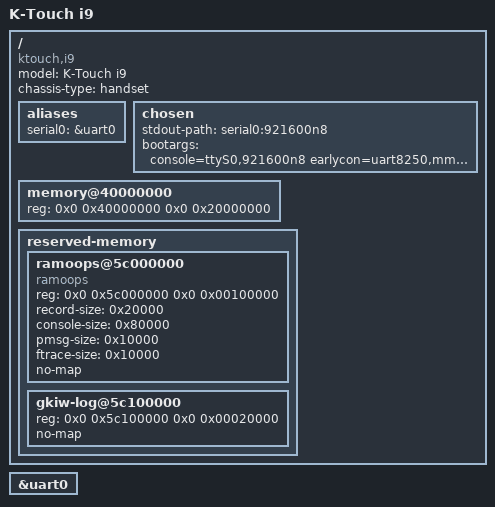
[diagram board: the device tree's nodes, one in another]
// SPDX-License-Identifier: GPL-2.0-only
/*
 * K-Touch i9 (MT6739)
 *
 * First mainline boot milestone: CPUs, GIC, timer, PSCI, UART and pstore.
 * The 2ndstage U-Boot boots this image at 0x45000000 and reserves the pstore
 * region below at 0x5c000000.
 */

/dts-v1/;

#include "mt6739.dtsi"

/ {
	model = "K-Touch i9";
	compatible = "ktouch,i9", "mediatek,mt6739";
	chassis-type = "handset";

	aliases {
		serial0 = &uart0;
	};

	chosen {
		stdout-path = "serial0:921600n8";
		bootargs = "console=ttyS0,921600n8 earlycon=uart8250,mmio32,0x11002000,921600n8 keep_bootcon ignore_loglevel loglevel=8";
	};

	memory@40000000 {
		device_type = "memory";
		reg = <0x0 0x40000000 0x0 0x20000000>; /* 512 MiB bringup floor */
	};

	reserved-memory {
		#address-cells = <2>;
		#size-cells = <2>;
		ranges;

		ramoops@5c000000 {
			compatible = "ramoops";
			reg = <0x0 0x5c000000 0x0 0x00100000>;
			record-size = <0x20000>;
			console-size = <0x80000>;
			pmsg-size = <0x10000>;
			ftrace-size = <0x10000>;
			no-map;
		};

		gkiw-log@5c100000 {
			reg = <0x0 0x5c100000 0x0 0x00020000>;
			no-map;
		};
	};
};

&uart0 {
	status = "okay";
};
